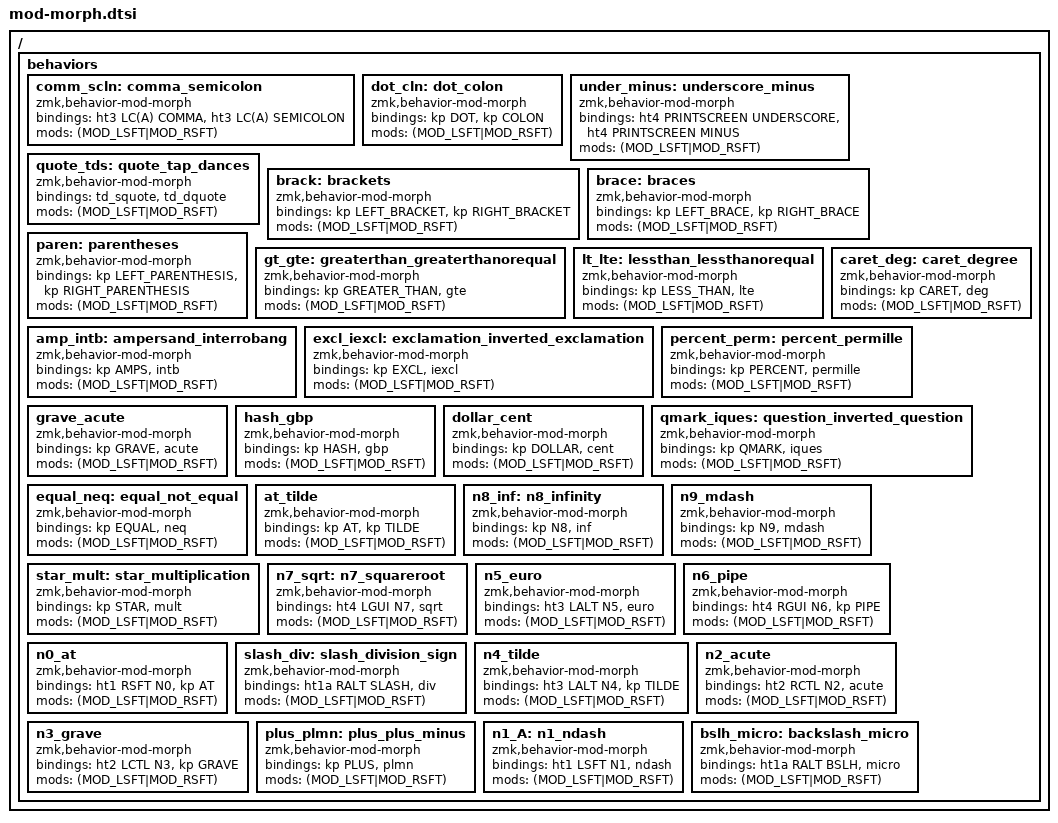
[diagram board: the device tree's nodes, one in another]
/ {
    behaviors {
		//bspc_del: backspace_delete {
		//	compatible = "zmk,behavior-mod-morph";
		//	#binding-cells = <0>;
		//	bindings = <&kp BACKSPACE>, <&kp DELETE>;
		//	mods = <(MOD_LSFT|MOD_RSFT)>;
		//};
		
		comm_scln: comma_semicolon {
			compatible = "zmk,behavior-mod-morph";
			#binding-cells = <0>;
			bindings = <&ht3 LC(A) COMMA>, <&ht3 LC(A) SEMICOLON>;
			mods = <(MOD_LSFT|MOD_RSFT)>;
		};

		dot_cln: dot_colon {
			compatible = "zmk,behavior-mod-morph";
			#binding-cells = <0>;
			bindings = <&kp DOT>, <&kp COLON>;
			mods = <(MOD_LSFT|MOD_RSFT)>;
		};
		
		under_minus: underscore_minus {
			compatible = "zmk,behavior-mod-morph";
			#binding-cells = <0>;
			bindings = <&ht4 PRINTSCREEN UNDERSCORE>, <&ht4 PRINTSCREEN MINUS>;
			mods = <(MOD_LSFT|MOD_RSFT)>;
		};

		quote_tds: quote_tap_dances {
			compatible = "zmk,behavior-mod-morph";
			#binding-cells = <0>;
			bindings = <&td_squote>, <&td_dquote>;
			mods = <(MOD_LSFT|MOD_RSFT)>;
		};

		brack: brackets {
			compatible = "zmk,behavior-mod-morph";
			#binding-cells = <0>;
			bindings = <&kp LEFT_BRACKET>, <&kp RIGHT_BRACKET>;
			mods = <(MOD_LSFT|MOD_RSFT)>;
		};

		brace: braces {
			compatible = "zmk,behavior-mod-morph";
			#binding-cells = <0>;
			bindings = <&kp LEFT_BRACE>, <&kp RIGHT_BRACE>;
			mods = <(MOD_LSFT|MOD_RSFT)>;
		};

		paren: parentheses {
			compatible = "zmk,behavior-mod-morph";
			#binding-cells = <0>;
			bindings = <&kp LEFT_PARENTHESIS>, <&kp RIGHT_PARENTHESIS>;
			mods = <(MOD_LSFT|MOD_RSFT)>;
		};

		gt_gte: greaterthan_greaterthanorequal {
			compatible = "zmk,behavior-mod-morph";
			#binding-cells = <0>;
			bindings = <&kp GREATER_THAN>, <&gte>;
			mods = <(MOD_LSFT|MOD_RSFT)>;
		};

		lt_lte: lessthan_lessthanorequal {
			compatible = "zmk,behavior-mod-morph";
			#binding-cells = <0>;
			bindings = <&kp LESS_THAN>, <&lte>;
			mods = <(MOD_LSFT|MOD_RSFT)>;
		};

		amp_intb: ampersand_interrobang {
			compatible = "zmk,behavior-mod-morph";
			#binding-cells = <0>;
			bindings = <&kp AMPS>, <&intb>;
			mods = <(MOD_LSFT|MOD_RSFT)>;
		};

		excl_iexcl: exclamation_inverted_exclamation {
			compatible = "zmk,behavior-mod-morph";
			#binding-cells = <0>;
			bindings = <&kp EXCL>, <&iexcl>;
			mods = <(MOD_LSFT|MOD_RSFT)>;
		};

		caret_deg: caret_degree {
			compatible = "zmk,behavior-mod-morph";
			#binding-cells = <0>;
			bindings = <&kp CARET>, <&deg>;
			mods = <(MOD_LSFT|MOD_RSFT)>;
		};

		percent_perm: percent_permille {
			compatible = "zmk,behavior-mod-morph";
			#binding-cells = <0>;
			bindings = <&kp PERCENT>, <&permille>;
			mods = <(MOD_LSFT|MOD_RSFT)>;
		};

		grave_acute: grave_acute {
			compatible = "zmk,behavior-mod-morph";
			#binding-cells = <0>;
			bindings = <&kp GRAVE>, <&acute>;
			mods = <(MOD_LSFT|MOD_RSFT)>;
		};

		hash_gbp: hash_gbp {
			compatible = "zmk,behavior-mod-morph";
			#binding-cells = <0>;
			bindings = <&kp HASH>, <&gbp>;
			mods = <(MOD_LSFT|MOD_RSFT)>;
		};

		dollar_cent: dollar_cent {
			compatible = "zmk,behavior-mod-morph";
			#binding-cells = <0>;
			bindings = <&kp DOLLAR>, <&cent>;
			mods = <(MOD_LSFT|MOD_RSFT)>;
		};

		qmark_iques: question_inverted_question {
			compatible = "zmk,behavior-mod-morph";
			#binding-cells = <0>;
			bindings = <&kp QMARK>, <&iques>;
			mods = <(MOD_LSFT|MOD_RSFT)>;
		};

		equal_neq: equal_not_equal {
			compatible = "zmk,behavior-mod-morph";
			#binding-cells = <0>;
			bindings = <&kp EQUAL>, <&neq>;
			mods = <(MOD_LSFT|MOD_RSFT)>;
		};

		at_tilde: at_tilde {
			compatible = "zmk,behavior-mod-morph";
			#binding-cells = <0>;
			bindings = <&kp AT>, <&kp TILDE>;
			mods = <(MOD_LSFT|MOD_RSFT)>;
		};

		n8_inf: n8_infinity {
			compatible = "zmk,behavior-mod-morph";
			#binding-cells = <0>;
			bindings = <&kp N8>, <&inf>;
			mods = <(MOD_LSFT|MOD_RSFT)>;
		};

		n9_mdash: n9_mdash {
			compatible = "zmk,behavior-mod-morph";
			#binding-cells = <0>;
			bindings = <&kp N9>, <&mdash>;
			mods = <(MOD_LSFT|MOD_RSFT)>;
		};

		star_mult: star_multiplication {
			compatible = "zmk,behavior-mod-morph";
			#binding-cells = <0>;
			bindings = <&kp STAR>, <&mult>;
			mods = <(MOD_LSFT|MOD_RSFT)>;
		};

		n7_sqrt: n7_squareroot {
			compatible = "zmk,behavior-mod-morph";
			#binding-cells = <0>;
			bindings = <&ht4 LGUI N7>, <&sqrt>;
			mods = <(MOD_LSFT|MOD_RSFT)>;
		};

		n5_euro: n5_euro {
			compatible = "zmk,behavior-mod-morph";
			#binding-cells = <0>;
			bindings = <&ht3 LALT N5>, <&euro>;
			mods = <(MOD_LSFT|MOD_RSFT)>;
		};

		n6_pipe: n6_pipe {
			compatible = "zmk,behavior-mod-morph";
			#binding-cells = <0>;
			bindings = <&ht4 RGUI N6>, <&kp PIPE>;
			mods = <(MOD_LSFT|MOD_RSFT)>;
		};

		n0_at: n0_at {
			compatible = "zmk,behavior-mod-morph";
			#binding-cells = <0>;
			bindings = <&ht1 RSFT N0>, <&kp AT>;
			mods = <(MOD_LSFT|MOD_RSFT)>;
		};

		slash_div: slash_division_sign {
			compatible = "zmk,behavior-mod-morph";
			#binding-cells = <0>;
			bindings = <&ht1a RALT SLASH>, <&div>;
			mods = <(MOD_LSFT|MOD_RSFT)>;
		};

		n4_tilde: n4_tilde {
			compatible = "zmk,behavior-mod-morph";
			#binding-cells = <0>;
			bindings = <&ht3 LALT N4>, <&kp TILDE>;
			mods = <(MOD_LSFT|MOD_RSFT)>;
		};

		n2_acute: n2_acute {
			compatible = "zmk,behavior-mod-morph";
			#binding-cells = <0>;
			bindings = <&ht2 RCTL N2>, <&acute>;
			mods = <(MOD_LSFT|MOD_RSFT)>;
		};

		n3_grave: n3_grave {
			compatible = "zmk,behavior-mod-morph";
			#binding-cells = <0>;
			bindings = <&ht2 LCTL N3>, <&kp GRAVE>;
			mods = <(MOD_LSFT|MOD_RSFT)>;
		};

		plus_plmn: plus_plus_minus {
			compatible = "zmk,behavior-mod-morph";
			#binding-cells = <0>;
			bindings = <&kp PLUS>, <&plmn>;
			mods = <(MOD_LSFT|MOD_RSFT)>;
		};

		n1_A: n1_ndash {
			compatible = "zmk,behavior-mod-morph";
			#binding-cells = <0>;
			bindings = <&ht1 LSFT N1>, <&ndash>;
			mods = <(MOD_LSFT|MOD_RSFT)>;
		};

		bslh_micro: backslash_micro {
			compatible = "zmk,behavior-mod-morph";
			#binding-cells = <0>;
			bindings = <&ht1a RALT BSLH>, <&micro>;
			mods = <(MOD_LSFT|MOD_RSFT)>;
		};
	};
};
